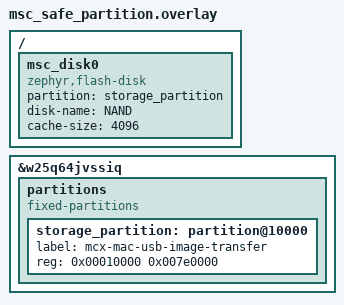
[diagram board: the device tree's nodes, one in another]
/* SPDX-License-Identifier: MIT */
/* Compile-only USB MSC feasibility probe. Never run it against the existing
 * Macintosh HFS disk: the host would see a non-FAT volume and may offer to
 * format it. Preserve the first and last 64 KiB of the W25Q64.
 */
/delete-node/ &storage_partition;

&w25q64jvssiq {
	partitions {
		compatible = "fixed-partitions";
		#address-cells = <1>;
		#size-cells = <1>;

		storage_partition: partition@10000 {
			label = "mcx-mac-usb-image-transfer";
			reg = <0x00010000 0x007e0000>;
		};
	};
};

/ {
	msc_disk0 {
		compatible = "zephyr,flash-disk";
		partition = <&storage_partition>;
		disk-name = "NAND";
		cache-size = <4096>;
	};
};
